# slabware register map
Slabware control system
Registers are 32-bit, read-only, reset 0x0 unless marked. A register's access mark holds for its fields unless they carry their own. Offsets are from the block's base; lines under a group give offsets from that group; [hi:lo] are bit positions; {n}, {i} and the like mark numbered series; 'fields as' and 'values as' point back to an identical list; <NAME> marks a mode.

## Memory map
0x10000000 Leds — LED control
0x10000400 Timer
0x10000800 Mi2c — I2C controller
0x10000C00 HdmiRX — HDMI Receiver
0x10001000 LcdDim — LCD dim control
0x10001400 GridCtrl — SlabGrid control
0x10010000 UsbCtrl — USB device controller

## Leds — LED control
Base 0x10000000
0x00 CTRL rw — LED output control
  [7:0] value read-modifies — LED output value

## Timer
Base 0x10000400
0x04 prescale wo
  [15:0] value read-modifies — Timer prescale divisor
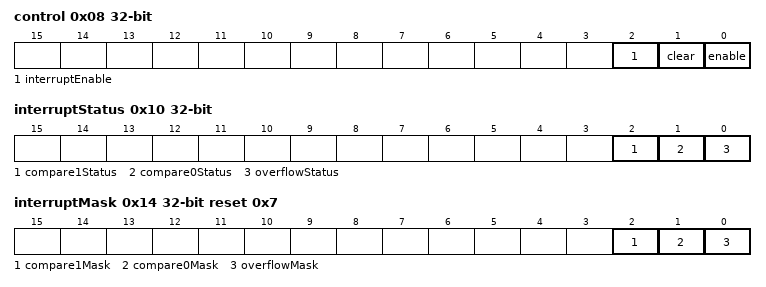
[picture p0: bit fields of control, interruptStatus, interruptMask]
0x08 control access per field
  [2] interruptEnable rw read-modifies
  [1] clear wo read-modifies — Clear prescaler and counter
  [0] enable rw read-modifies — Timer enable
0x0C counter rw
  [15:0] counter read-modifies — Counter value
0x10 interruptStatus rw
  [2] compare1Status write-1-clears read-modifies — Compare1 interrupt status (set to clear)
  [1] compare0Status write-1-clears read-modifies — Compare0 interrupt status (set to clear)
  [0] overflowStatus write-1-clears read-modifies — Overflow interrupt status (set to clear)
0x14 interruptMask rw reset 0x7
  [2] compare1Mask read-modifies — Mask compare1 interrupt
  [1] compare0Mask read-modifies — Mask compare0 interrupt
  [0] overflowMask read-modifies — Mask overflow interrupt
0x18 compare0 rw
  [15:0] value read-modifies — Compare 0 value
0x1C compare1 rw
  [15:0] value read-modifies — Compare 1 value

## Mi2c — I2C controller
Base 0x10000800
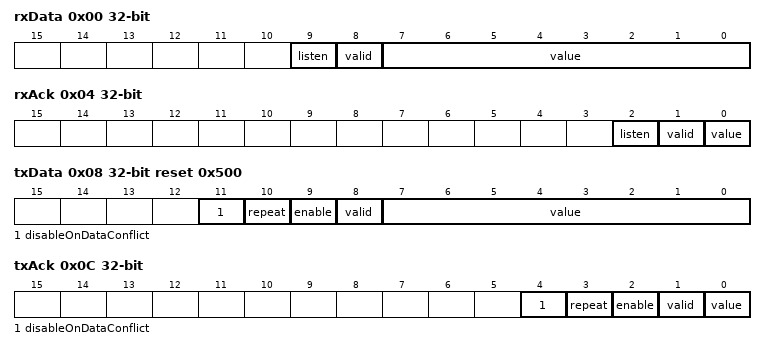
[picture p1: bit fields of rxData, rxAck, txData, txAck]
0x00 rxData access per field — Receive data
  [9] listen wo read-modifies — Listen for receive data
  [8] valid ro read-clears — Receive data valid (cleared on read)
  [7:0] value ro read-modifies — Receive data value
0x04 rxAck access per field — Receive acknowledge
  [2] listen wo read-modifies — Listen for receive acknowledge
  [1] valid ro read-clears — Receive acknowledge valid (cleared on read)
  [0] value ro read-modifies — Receive acknowledge value
0x08 txData access per field reset 0x500 — Transmit data
  [11] disableOnDataConflict wo read-modifies
  [10] repeat wo read-modifies — Transmit data repeat
  [9] enable rw read-modifies — Transmit data enable
  [8] valid rw read-modifies — Transmit data valid
  [7:0] value wo read-modifies — Transmit data value
0x0C txAck access per field — Transmit acknowledge
  [4] disableOnDataConflict wo read-modifies
  [3] repeat wo read-modifies — Transmit acknowledge repeat
  [2] enable rw read-modifies — Transmit acknowledge enable
  [1] valid rw read-modifies — Transmit acknowledge valid
  [0] value wo read-modifies — Transmit acknowledge value
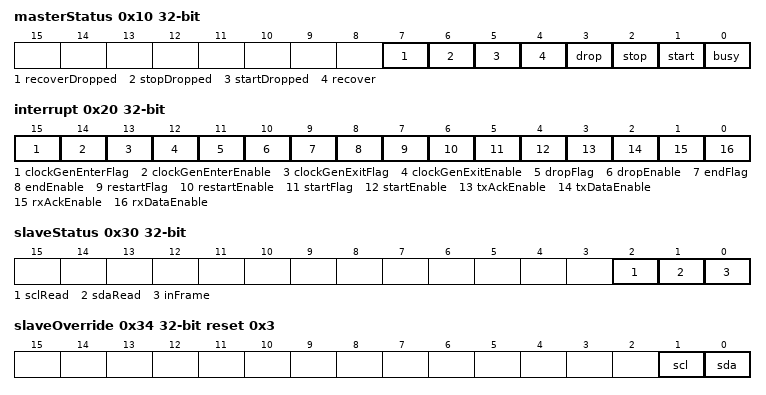
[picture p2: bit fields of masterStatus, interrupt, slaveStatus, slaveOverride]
0x10 masterStatus access per field
  [7] recoverDropped rw write-1-clears read-modifies — Timeout during recover
  [6] stopDropped rw write-1-clears read-modifies — Timeout during stop
  [5] startDropped rw write-1-clears read-modifies — Timeout during start
  [4] recover rw write-1-sets read-modifies — Order a recover (set on set)
  [3] drop rw write-1-sets read-modifies — Order a drop (set on set)
  [2] stop rw write-1-sets read-modifies — Order a stop (set on set)
  [1] start rw write-1-sets read-modifies — Order a start (set on set)
  [0] busy ro read-modifies — Is busy?
0x14 TLOW wo — I2C low timing
  [15:0] tLow read-modifies — # of cycles low
0x18 THIGH wo — I2C high timing
  [15:0] tHigh read-modifies — # of cycles high
0x1C TBUF wo — I2C idle timing
  [15:0] tBuf read-modifies — # of cycles idle
0x20 interrupt rw — Interrupt control
  [15] clockGenEnterFlag write-1-clears read-modifies
  [14] clockGenEnterEnable read-modifies
  [13] clockGenExitFlag write-1-clears read-modifies
  [12] clockGenExitEnable read-modifies
  [11] dropFlag write-1-clears read-modifies — I2C Drop flag
  [10] dropEnable read-modifies — I2C Drop enable
  [9] endFlag write-1-clears read-modifies — I2C END flag
  [8] endEnable read-modifies — I2C END enable
  [7] restartFlag write-1-clears read-modifies — I2C Restart flag
  [6] restartEnable read-modifies — I2C Restart enable
  [5] startFlag write-1-clears read-modifies — I2C Start flag
  [4] startEnable read-modifies — I2C Start enable
  [3] txAckEnable read-modifies — TX ack interrupt enable
  [2] txDataEnable read-modifies — TX data interrupt enable
  [1] rxAckEnable read-modifies — RX ack interrupt enable
  [0] rxDataEnable read-modifies — RX data interrupt enable
0x24 samplingClockDivider wo — Sampling clock
  [9:0] samplingClockDivider read-modifies
0x28 TIMEOUT wo
  [19:0] timeout read-modifies
0x2C tsuData wo
  [5:0] tsuData read-modifies
0x30 slaveStatus
  [2] sclRead read-modifies, [1] sdaRead read-modifies, [0] inFrame read-modifies
0x34 slaveOverride rw reset 0x3
  [1] scl read-modifies — Force the SCL pin low when cleared
  [0] sda read-modifies — Force the SDA pin low when cleared
